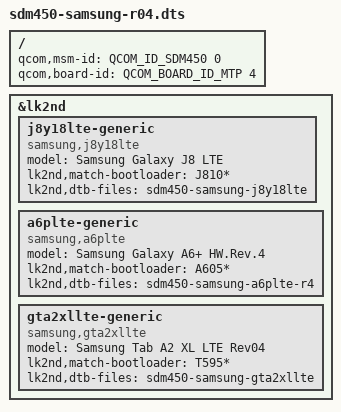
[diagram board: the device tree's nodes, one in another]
// SPDX-License-Identifier: GPL-2.0-only

/dts-v1/;

#include "sdm450-samsung.dtsi"

/ {
	qcom,msm-id = <QCOM_ID_SDM450 0>;
	qcom,board-id = <QCOM_BOARD_ID_MTP 4>;
};

&lk2nd {
	j8y18lte-generic {
		model = "Samsung Galaxy J8 LTE";
		compatible = "samsung,j8y18lte";
		lk2nd,match-bootloader = "J810*";

		lk2nd,dtb-files = "sdm450-samsung-j8y18lte";
	};

	a6plte-generic {
		model = "Samsung Galaxy A6+ HW.Rev.4";
		compatible = "samsung,a6plte";
		lk2nd,match-bootloader = "A605*";

		lk2nd,dtb-files = "sdm450-samsung-a6plte-r4";
	};

	gta2xllte-generic {
		model = "Samsung Tab A2 XL LTE Rev04";
		compatible = "samsung,gta2xllte";
		lk2nd,match-bootloader = "T595*";

		lk2nd,dtb-files = "sdm450-samsung-gta2xllte";
	};
};
